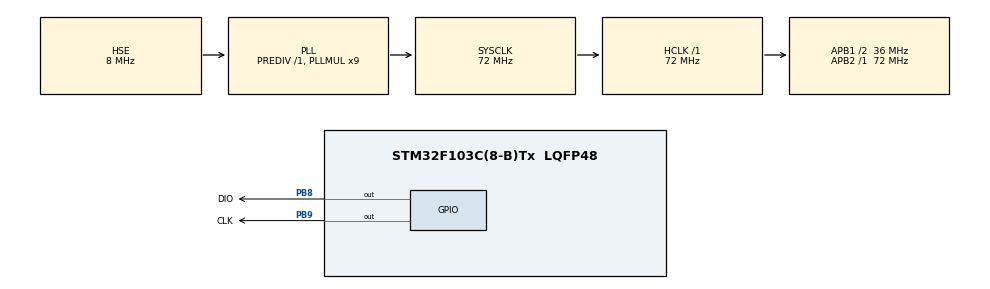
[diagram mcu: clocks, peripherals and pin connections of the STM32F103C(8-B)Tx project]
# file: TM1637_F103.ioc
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Mcu.Family=STM32F1
Mcu.Name=STM32F103C(8-B)Tx
Mcu.Package=LQFP48
NVIC.PriorityGroup=NVIC_PRIORITYGROUP_4
PA13.Mode=Serial_Wire
PA13.Signal=SYS_JTMS-SWDIO
PA14.Mode=Serial_Wire
PA14.Signal=SYS_JTCK-SWCLK
PB8.GPIO_Label=DIO
PB8.GPIO_ModeDefaultOutputPP=GPIO_MODE_OUTPUT_OD
PB8.GPIO_PuPd=GPIO_PULLUP
PB8.GPIO_Speed=GPIO_SPEED_FREQ_LOW
PB8.Signal=GPIO_Output
PB9.GPIO_Label=CLK
PB9.GPIO_ModeDefaultOutputPP=GPIO_MODE_OUTPUT_OD
PB9.GPIO_PuPd=GPIO_PULLUP
PB9.GPIO_Speed=GPIO_SPEED_FREQ_LOW
PB9.Signal=GPIO_Output
PC14-OSC32_IN.Mode=LSE-External-Oscillator
PC14-OSC32_IN.Signal=RCC_OSC32_IN
PC15-OSC32_OUT.Mode=LSE-External-Oscillator
PC15-OSC32_OUT.Signal=RCC_OSC32_OUT
PD0-OSC_IN.Mode=HSE-External-Oscillator
PD0-OSC_IN.Signal=RCC_OSC_IN
PD1-OSC_OUT.Mode=HSE-External-Oscillator
PD1-OSC_OUT.Signal=RCC_OSC_OUT
ProjectManager.HeapSize=0x200
ProjectManager.StackSize=0x400
ProjectManager.TargetToolchain=TrueSTUDIO
RCC.AHBFreq_Value=72000000
RCC.APB1CLKDivider=RCC_HCLK_DIV2
RCC.APB1Freq_Value=36000000
RCC.APB1TimFreq_Value=72000000
RCC.APB2Freq_Value=72000000
RCC.APB2TimFreq_Value=72000000
RCC.HCLKFreq_Value=72000000
RCC.PLLMUL=RCC_PLL_MUL9
RCC.PLLSourceVirtual=RCC_PLLSOURCE_HSE
RCC.RTCClockSelection=RCC_RTCCLKSOURCE_LSE
RCC.SYSCLKFreq_VALUE=72000000
RCC.SYSCLKSource=RCC_SYSCLKSOURCE_PLLCLK
RCC.USBFreq_Value=72000000
RTC.Format=RTC_FORMAT_BIN
RTC.Hours=6
RTC.Minutes=43
VP_RTC_VS_RTC_Activate.Mode=RTC_Enabled
VP_RTC_VS_RTC_Calendar.Mode=RTC_Calendar
board=custom

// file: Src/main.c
/* USER CODE BEGIN Header */
/**
  ******************************************************************************
  * @file           : main.c
  * @brief          : Main program body
  ******************************************************************************
  * @attention
  *
  * <h2><center>&copy; Copyright (c) 2019 STMicroelectronics.
  * All rights reserved.</center></h2>
  *
  * This software component is licensed by ST under BSD 3-Clause license,
  * the "License"; You may not use this file except in compliance with the
  * License. You may obtain a copy of the License at:
  *                        opensource.org/licenses/BSD-3-Clause
  *
  ******************************************************************************
  */
/* USER CODE END Header */

#include "main.h"

/* USER CODE BEGIN Includes */
#include "delay_micros.h"
#include "tm1637.h"
/* USER CODE END Includes */

RTC_HandleTypeDef hrtc;

void SystemClock_Config(void);
static void MX_GPIO_Init(void);
static void MX_RTC_Init(void);

int main(void)
{

  /* MCU Configuration--------------------------------------------------------*/

  /* Reset of all peripherals, Initializes the Flash interface and the Systick. */
  HAL_Init();

  /* Configure the system clock */
  SystemClock_Config();

  /* Initialize all configured peripherals */
  MX_GPIO_Init();
  MX_RTC_Init();
  /* USER CODE BEGIN 2 */
  DWT_Init();        // инициализация DWT
  set_brightness(7); // 0 - 7 яркость
  clearDisplay();    // очистка дисплея

  RTC_TimeTypeDef sTime = {0};           // структура для времени
  // RTC_DateTypeDef DateToUpdate = {0}; // если микроконтроллер F4xx или F7xx

  int8_t TimeDisp[4] = {0,};
  /* USER CODE END 2 */

  /* Infinite loop */
  /* USER CODE BEGIN WHILE */
  while (1)
  {
	  HAL_RTC_GetTime(&hrtc, &sTime, RTC_FORMAT_BIN);
	  // HAL_RTC_GetDate(&hrtc, &DateToUpdate, RTC_FORMAT_BIN); // если микроконтроллер F4xx или F7xx

	  point(0); // двоеточие, 0 - мигает, 1 - горит постоянно, удалить функцию - нет двоеточия

	  TimeDisp[0] = sTime.Hours / 10;
	  TimeDisp[1] = sTime.Hours % 10;
	  TimeDisp[2] = sTime.Minutes / 10;
	  TimeDisp[3] = sTime.Minutes % 10;
	  display_mass(TimeDisp);

	  HAL_Delay(1000);

	  // выведет символ А в первой ячейке и b в третьей
	  /*TimeDisp[0] = 10;
	  TimeDisp[1] = 0x7f;
	  TimeDisp[2] = 11;
	  TimeDisp[3] = 0x7f;
	  display_mass(TimeDisp);
	  HAL_Delay(1000);*/

	  // выведет -23
	  /*TimeDisp[0] = 0x7f;
	  TimeDisp[1] = 12;
	  TimeDisp[2] = 23 / 10;
	  TimeDisp[3] = 23 % 10;
	  display_mass(TimeDisp);
	  HAL_Delay(1000);*/

    /* USER CODE END WHILE */

  }
}

void SystemClock_Config(void)
{
  RCC_OscInitTypeDef RCC_OscInitStruct = {0};
  RCC_ClkInitTypeDef RCC_ClkInitStruct = {0};
  RCC_PeriphCLKInitTypeDef PeriphClkInit = {0};

  /** Initializes the CPU, AHB and APB busses clocks
  */
  RCC_OscInitStruct.OscillatorType = RCC_OSCILLATORTYPE_HSE|RCC_OSCILLATORTYPE_LSE;
  RCC_OscInitStruct.HSEState = RCC_HSE_ON;
  RCC_OscInitStruct.HSEPredivValue = RCC_HSE_PREDIV_DIV1;
  RCC_OscInitStruct.LSEState = RCC_LSE_ON;
  RCC_OscInitStruct.HSIState = RCC_HSI_ON;
  RCC_OscInitStruct.PLL.PLLState = RCC_PLL_ON;
  RCC_OscInitStruct.PLL.PLLSource = RCC_PLLSOURCE_HSE;
  RCC_OscInitStruct.PLL.PLLMUL = RCC_PLL_MUL9;
  if (HAL_RCC_OscConfig(&RCC_OscInitStruct) != HAL_OK)
  {
    Error_Handler();
  }
  /** Initializes the CPU, AHB and APB busses clocks
  */
  RCC_ClkInitStruct.ClockType = RCC_CLOCKTYPE_HCLK|RCC_CLOCKTYPE_SYSCLK
                              |RCC_CLOCKTYPE_PCLK1|RCC_CLOCKTYPE_PCLK2;
  RCC_ClkInitStruct.SYSCLKSource = RCC_SYSCLKSOURCE_PLLCLK;
  RCC_ClkInitStruct.AHBCLKDivider = RCC_SYSCLK_DIV1;
  RCC_ClkInitStruct.APB1CLKDivider = RCC_HCLK_DIV2;
  RCC_ClkInitStruct.APB2CLKDivider = RCC_HCLK_DIV1;

  if (HAL_RCC_ClockConfig(&RCC_ClkInitStruct, FLASH_LATENCY_2) != HAL_OK)
  {
    Error_Handler();
  }
  PeriphClkInit.PeriphClockSelection = RCC_PERIPHCLK_RTC;
  PeriphClkInit.RTCClockSelection = RCC_RTCCLKSOURCE_LSE;
  if (HAL_RCCEx_PeriphCLKConfig(&PeriphClkInit) != HAL_OK)
  {
    Error_Handler();
  }
}

static void MX_RTC_Init(void)
{

  RTC_TimeTypeDef sTime = {0};
  RTC_DateTypeDef DateToUpdate = {0};

  /** Initialize RTC Only
  */
  hrtc.Instance = RTC;
  hrtc.Init.AsynchPrediv = RTC_AUTO_1_SECOND;
  hrtc.Init.OutPut = RTC_OUTPUTSOURCE_ALARM;
  if (HAL_RTC_Init(&hrtc) != HAL_OK)
  {
    Error_Handler();
  }

  /** Initialize RTC and set the Time and Date
  */
  sTime.Hours = 6;
  sTime.Minutes = 43;
  sTime.Seconds = 0;

  if (HAL_RTC_SetTime(&hrtc, &sTime, RTC_FORMAT_BIN) != HAL_OK)
  {
    Error_Handler();
  }
  DateToUpdate.WeekDay = RTC_WEEKDAY_MONDAY;
  DateToUpdate.Month = RTC_MONTH_JANUARY;
  DateToUpdate.Date = 1;
  DateToUpdate.Year = 0;

  if (HAL_RTC_SetDate(&hrtc, &DateToUpdate, RTC_FORMAT_BIN) != HAL_OK)
  {
    Error_Handler();
  }

}

static void MX_GPIO_Init(void)
{
  GPIO_InitTypeDef GPIO_InitStruct = {0};

  /* GPIO Ports Clock Enable */
  __HAL_RCC_GPIOC_CLK_ENABLE();
  __HAL_RCC_GPIOD_CLK_ENABLE();
  __HAL_RCC_GPIOA_CLK_ENABLE();
  __HAL_RCC_GPIOB_CLK_ENABLE();

  /*Configure GPIO pin Output Level */
  HAL_GPIO_WritePin(GPIOB, DIO_Pin|CLK_Pin, GPIO_PIN_RESET);

  /*Configure GPIO pins : DIO_Pin CLK_Pin */
  GPIO_InitStruct.Pin = DIO_Pin|CLK_Pin;
  GPIO_InitStruct.Mode = GPIO_MODE_OUTPUT_OD;
  GPIO_InitStruct.Pull = GPIO_PULLUP;
  GPIO_InitStruct.Speed = GPIO_SPEED_FREQ_LOW;
  HAL_GPIO_Init(GPIOB, &GPIO_InitStruct);

}

void Error_Handler(void)
{
}

/************************ (C) COPYRIGHT STMicroelectronics *****END OF FILE****/
